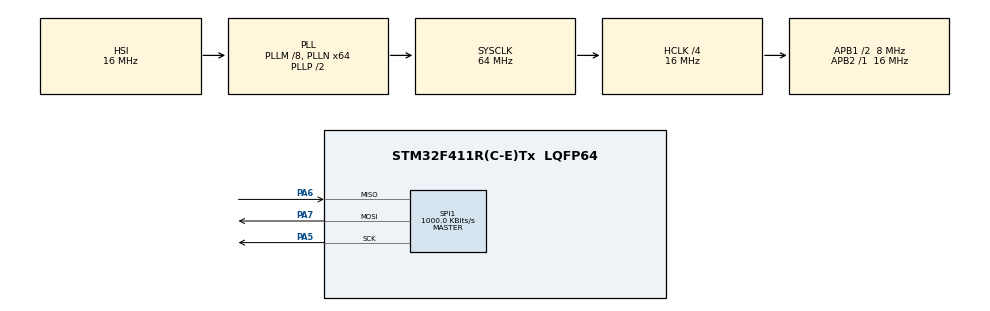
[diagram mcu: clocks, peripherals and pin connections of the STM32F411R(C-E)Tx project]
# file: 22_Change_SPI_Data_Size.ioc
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Mcu.Family=STM32F4
Mcu.Name=STM32F411R(C-E)Tx
Mcu.Package=LQFP64
NVIC.PriorityGroup=NVIC_PRIORITYGROUP_0
PA5.Mode=Full_Duplex_Master
PA5.Signal=SPI1_SCK
PA6.Mode=Full_Duplex_Master
PA6.Signal=SPI1_MISO
PA7.Mode=Full_Duplex_Master
PA7.Signal=SPI1_MOSI
ProjectManager.HeapSize=0x200
ProjectManager.StackSize=0x400
ProjectManager.TargetToolchain=STM32CubeIDE
RCC.48MHZClocksFreq_Value=32000000
RCC.AHBCLKDivider=RCC_SYSCLK_DIV4
RCC.AHBFreq_Value=16000000
RCC.APB1CLKDivider=RCC_HCLK_DIV2
RCC.APB1Freq_Value=8000000
RCC.APB1TimFreq_Value=16000000
RCC.APB2Freq_Value=16000000
RCC.APB2TimFreq_Value=16000000
RCC.CortexFreq_Value=16000000
RCC.FLatency-AdvancedSettings=FLASH_LATENCY_0
RCC.HCLKFreq_Value=16000000
RCC.HSE_VALUE=8000000
RCC.HSI_VALUE=16000000
RCC.PLLM=8
RCC.PLLN=64
RCC.SYSCLKFreq_VALUE=64000000
RCC.SYSCLKSource=RCC_SYSCLKSOURCE_PLLCLK
RCC.VCOOutputFreq_Value=128000000
SPI1.BaudRatePrescaler=SPI_BAUDRATEPRESCALER_16
SPI1.CalculateBaudRate=1000.0 KBits/s
SPI1.Direction=SPI_DIRECTION_2LINES
SPI1.Mode=SPI_MODE_MASTER
SPI1.VirtualType=VM_MASTER
board=NUCLEO-F411RE

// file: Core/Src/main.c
/* USER CODE BEGIN Header */
/**
  ******************************************************************************
  * @file           : main.c
  * @brief          : Main program body
  ******************************************************************************
  * @attention
  *
  * Copyright (c) 2024 STMicroelectronics.
  * All rights reserved.
  *
  * This software is licensed under terms that can be found in the LICENSE file
  * in the root directory of this software component.
  * If no LICENSE file comes with this software, it is provided AS-IS.
  *
  ******************************************************************************
  */
/* USER CODE END Header */
#include "main.h"

SPI_HandleTypeDef hspi1;

/* USER CODE BEGIN PV */

uint8_t tx_data[4] = {1, 2, 3, 4};
uint8_t rx_data[4];

uint16_t tx_data16[2] = {0x24AB, 0x52CB};
uint16_t rx_data16[2];

/* USER CODE END PV */

void SystemClock_Config(void);
static void MX_GPIO_Init(void);
static void MX_SPI1_Init(void);
/* USER CODE BEGIN PFP */

void change_SPI_Data_Size(SPI_HandleTypeDef *hspi, uint16_t SPI_SIZE);
/* USER CODE END PFP */

int main(void)
{

  /* MCU Configuration--------------------------------------------------------*/

  /* Reset of all peripherals, Initializes the Flash interface and the Systick. */
  HAL_Init();

  /* Configure the system clock */
  SystemClock_Config();

  /* Initialize all configured peripherals */
  MX_GPIO_Init();
  MX_SPI1_Init();

  /* Infinite loop */
  while (1)
  {

    /* USER CODE BEGIN 3 */
	  HAL_SPI_TransmitReceive(&hspi1, tx_data, rx_data, 4, HAL_MAX_DELAY);
	  change_SPI_Data_Size(&hspi1, SPI_DATASIZE_16BIT);
	  HAL_SPI_TransmitReceive(&hspi1, (uint8_t*)tx_data16, (uint8_t*)rx_data16, 2, HAL_MAX_DELAY);
	  change_SPI_Data_Size(&hspi1, SPI_DATASIZE_8BIT);
  }
  /* USER CODE END 3 */
}

void SystemClock_Config(void)
{
  RCC_OscInitTypeDef RCC_OscInitStruct = {0};
  RCC_ClkInitTypeDef RCC_ClkInitStruct = {0};

  /** Configure the main internal regulator output voltage
  */
  __HAL_RCC_PWR_CLK_ENABLE();
  __HAL_PWR_VOLTAGESCALING_CONFIG(PWR_REGULATOR_VOLTAGE_SCALE1);

  /** Initializes the RCC Oscillators according to the specified parameters
  * in the RCC_OscInitTypeDef structure.
  */
  RCC_OscInitStruct.OscillatorType = RCC_OSCILLATORTYPE_HSI;
  RCC_OscInitStruct.HSIState = RCC_HSI_ON;
  RCC_OscInitStruct.HSICalibrationValue = RCC_HSICALIBRATION_DEFAULT;
  RCC_OscInitStruct.PLL.PLLState = RCC_PLL_ON;
  RCC_OscInitStruct.PLL.PLLSource = RCC_PLLSOURCE_HSI;
  RCC_OscInitStruct.PLL.PLLM = 8;
  RCC_OscInitStruct.PLL.PLLN = 64;
  RCC_OscInitStruct.PLL.PLLP = RCC_PLLP_DIV2;
  RCC_OscInitStruct.PLL.PLLQ = 4;
  if (HAL_RCC_OscConfig(&RCC_OscInitStruct) != HAL_OK)
  {
    Error_Handler();
  }

  /** Initializes the CPU, AHB and APB buses clocks
  */
  RCC_ClkInitStruct.ClockType = RCC_CLOCKTYPE_HCLK|RCC_CLOCKTYPE_SYSCLK
                              |RCC_CLOCKTYPE_PCLK1|RCC_CLOCKTYPE_PCLK2;
  RCC_ClkInitStruct.SYSCLKSource = RCC_SYSCLKSOURCE_PLLCLK;
  RCC_ClkInitStruct.AHBCLKDivider = RCC_SYSCLK_DIV4;
  RCC_ClkInitStruct.APB1CLKDivider = RCC_HCLK_DIV2;
  RCC_ClkInitStruct.APB2CLKDivider = RCC_HCLK_DIV1;

  if (HAL_RCC_ClockConfig(&RCC_ClkInitStruct, FLASH_LATENCY_0) != HAL_OK)
  {
    Error_Handler();
  }
}

static void MX_SPI1_Init(void)
{

  /* SPI1 parameter configuration*/
  hspi1.Instance = SPI1;
  hspi1.Init.Mode = SPI_MODE_MASTER;
  hspi1.Init.Direction = SPI_DIRECTION_2LINES;
  hspi1.Init.DataSize = SPI_DATASIZE_8BIT;
  hspi1.Init.CLKPolarity = SPI_POLARITY_LOW;
  hspi1.Init.CLKPhase = SPI_PHASE_1EDGE;
  hspi1.Init.NSS = SPI_NSS_SOFT;
  hspi1.Init.BaudRatePrescaler = SPI_BAUDRATEPRESCALER_16;
  hspi1.Init.FirstBit = SPI_FIRSTBIT_MSB;
  hspi1.Init.TIMode = SPI_TIMODE_DISABLE;
  hspi1.Init.CRCCalculation = SPI_CRCCALCULATION_DISABLE;
  hspi1.Init.CRCPolynomial = 10;
  if (HAL_SPI_Init(&hspi1) != HAL_OK)
  {
    Error_Handler();
  }

}

static void MX_GPIO_Init(void)
{

  /* GPIO Ports Clock Enable */
  __HAL_RCC_GPIOA_CLK_ENABLE();

}

/* USER CODE BEGIN 4 */

void change_SPI_Data_Size(SPI_HandleTypeDef *hspi, uint16_t SPI_SIZE)
{
	__HAL_SPI_DISABLE(hspi);

    HAL_SPI_DeInit(hspi);
    hspi->Init.DataSize = SPI_SIZE;
    HAL_SPI_Init(hspi);

    __HAL_SPI_ENABLE(hspi);
}

/* USER CODE END 4 */

void Error_Handler(void)
{
  __disable_irq();
  while (1)
  {
  }
}
